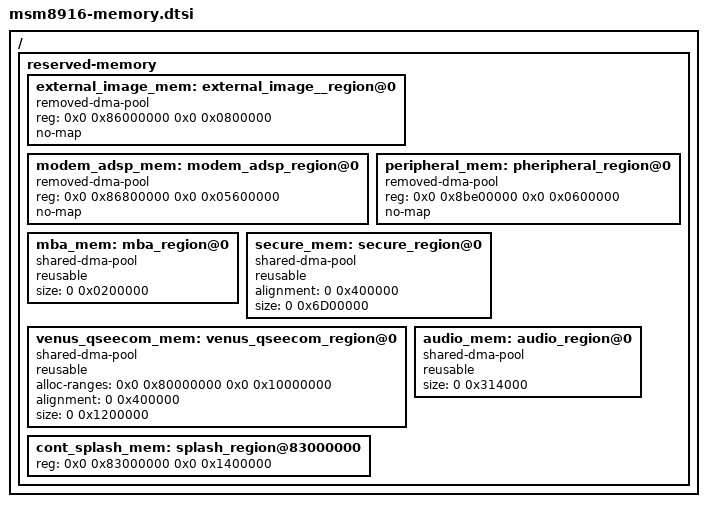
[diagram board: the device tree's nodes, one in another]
/* Copyright (c) 2014, The Linux Foundation. All rights reserved.
 *
 * This program is free software; you can redistribute it and/or modify
 * it under the terms of the GNU General Public License version 2 and
 * only version 2 as published by the Free Software Foundation.
 *
 * This program is distributed in the hope that it will be useful,
 * but WITHOUT ANY WARRANTY; without even the implied warranty of
 * MERCHANTABILITY or FITNESS FOR A PARTICULAR PURPOSE.  See the
 * GNU General Public License for more details.
 */

#include "msm8916-ion.dtsi"

/ {
	reserved-memory {
		#address-cells = <2>;
		#size-cells = <2>;
		ranges;

		external_image_mem: external_image__region@0 {
			reg = <0x0 0x86000000 0x0 0x0800000>;
			compatible = "removed-dma-pool";
			no-map;
		};

		modem_adsp_mem: modem_adsp_region@0 {
			reg = <0x0 0x86800000 0x0 0x05600000>;
			compatible = "removed-dma-pool";
			no-map;
		};

		peripheral_mem: pheripheral_region@0 {
			reg = <0x0 0x8be00000 0x0 0x0600000>;
			compatible = "removed-dma-pool";
			no-map;
		};

		mba_mem: mba_region@0 {
			compatible = "shared-dma-pool";
			reusable;
			size = <0 0x0200000>;
		};

		secure_mem: secure_region@0 {
			compatible = "shared-dma-pool";
			reusable;
			alignment = <0 0x400000>;
			size = <0 0x6D00000>;
		};

		venus_qseecom_mem: venus_qseecom_region@0 {
			compatible = "shared-dma-pool";
			reusable;
			alloc-ranges = <0x0 0x80000000 0x0 0x10000000>;
			alignment = <0 0x400000>;
			size = <0 0x1200000>;
		};

		audio_mem: audio_region@0 {
			compatible = "shared-dma-pool";
			reusable;
			size = <0 0x314000>;
		};

		cont_splash_mem: splash_region@83000000 {
			reg = <0x0 0x83000000 0x0 0x1400000>;
		};
	};
};
